# STM32F0x2 register map
File version: 1.3
CPU: CM0 r0p0, little endian, no MPU, no FPU, 2 interrupt priority bits
Registers are 32-bit, read-write, reset 0x0 unless marked. A register's access mark holds for its fields unless they carry their own. Offsets are from the block's base; [hi:lo] are bit positions; {n}, {i} and the like mark numbered series.

## WWDG — Window watchdog
Base 0x40002C00
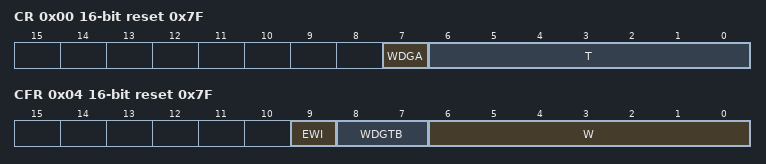
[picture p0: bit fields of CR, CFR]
0x00 CR 16-bit reset 0x7F — Control register
  [7] WDGA — Activation bit
    0=Disabled (Watchdog disabled); 1=Enabled (Watchdog enabled)
  [6:0] T — 7-bit counter
0x04 CFR 16-bit reset 0x7F — Configuration register
  [9] EWI — Early wakeup interrupt
    on write: 1=Enable (interrupt occurs whenever the counter reaches the value 0x40)
  [8:7] WDGTB — Timer base
    0=Div1 (Counter clock (PCLK1 div 4096) div 1); 1=Div2 (Counter clock (PCLK1 div 4096) div 2); 2=Div4 (Counter clock (PCLK1 div 4096) div 4); 3=Div8 (Counter clock (PCLK1 div 4096) div 8)
  [6:0] W — 7-bit window value
0x08 SR 16-bit — Status register
  [0] EWIF write-0-clears — Early wakeup interrupt flag
    on read: 0=Finished (The EWI Interrupt Service Routine has been serviced); 1=Pending (The EWI Interrupt Service Routine has been triggered) | on write: 0=Finished (The EWI Interrupt Service Routine has been serviced)

## TIM6 — Basic-timers
Base 0x40001000
Same registers: TIM7 0x40001400
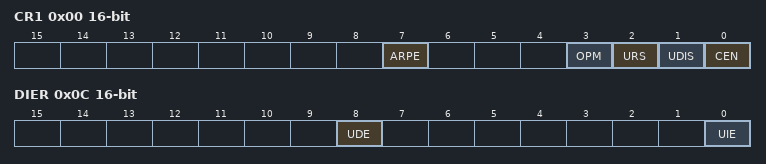
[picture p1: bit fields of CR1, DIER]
0x00 CR1 16-bit — control register 1
  [7] ARPE — Auto-reload preload enable
    0=Disabled (TIMx_APRR register is not buffered); 1=Enabled (TIMx_APRR register is buffered)
  [3] OPM — One-pulse mode
    0=Disabled (Counter is not stopped at update event); 1=Enabled (Counter stops counting at the next update event (clearing the CEN bit))
  [2] URS — Update request source
    0=AnyEvent (Any of counter overflow/underflow, setting UG, or update through slave mode, generates an update interrupt or DMA request); 1=CounterOnly (Only counter overflow/underflow generates an update interrupt or DMA request)
  [1] UDIS — Update disable
    0=Enabled (Update event enabled); 1=Disabled (Update event disabled)
  [0] CEN — Counter enable
    0=Disabled (Counter disabled); 1=Enabled (Counter enabled)
0x04 CR2 16-bit — control register 2
  [6:4] MMS — Master mode selection
    0=Reset (Use UG bit from TIMx_EGR register); 1=Enable (Use CNT bit from TIMx_CEN register); 2=Update (Use the update event)
0x0C DIER 16-bit — DMA/Interrupt enable register
  [8] UDE — Update DMA request enable
    0=Disabled (Update DMA request disabled); 1=Enabled (Update DMA request enabled)
  [0] UIE — Update interrupt enable
    0=Disabled (Update interrupt disabled); 1=Enabled (Update interrupt enabled)
0x10 SR 16-bit — status register
  [0] UIF write-0-clears — Update interrupt flag
    on read: 0=NoUpdateOccurred; 1=UpdatePending (Update interrupt pending) | on write: 0=Clear flag
0x14 EGR 16-bit wo — event generation register
  [0] UG — Update generation
    1=Update (Re-initializes the timer counter and generates an update of the registers.)
0x24 CNT 16-bit — counter
  [15:0] CNT — Low counter value
0x28 PSC 16-bit — prescaler
  [15:0] PSC — Prescaler value
0x2C ARR 16-bit reset 0xFFFF — auto-reload register
  [15:0] ARR — Low Auto-reload value

## EXTI — External interrupt/event controller
Base 0x40010400
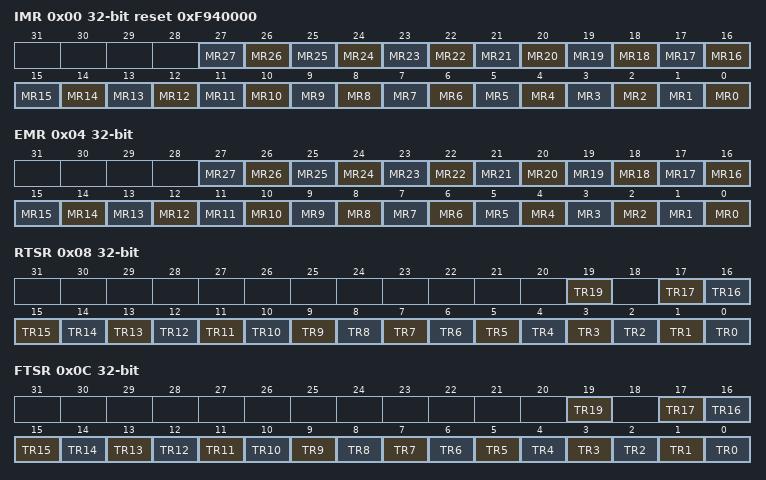
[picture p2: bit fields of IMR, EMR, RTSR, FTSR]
0x00 IMR reset 0xF940000 — Interrupt mask register (EXTI_IMR)
  [all] fields
    0=Masked (Interrupt request line is masked); 1=Unmasked (Interrupt request line is unmasked)
  [n] MR{n} (n=0..27) — Interrupt Mask on line {n}
0x04 EMR — Event mask register (EXTI_EMR)
  [all] fields
    0=Masked (Event request line is masked); 1=Unmasked (Event request line is unmasked)
  [n] MR{n} (n=0..27) — Event Mask on line {n}
0x08 RTSR — Rising Trigger selection register (EXTI_RTSR)
  [all] fields
    0=Disabled (Rising edge trigger is disabled); 1=Enabled (Rising edge trigger is enabled)
  [19] TR19 — Rising trigger event configuration of line 19
  [n] TR{n} (n=0..17) — Rising trigger event configuration of line {n}
0x0C FTSR — Falling Trigger selection register (EXTI_FTSR)
  [all] fields
    0=Disabled (Falling edge trigger is disabled); 1=Enabled (Falling edge trigger is enabled)
  [19] TR19 — Falling trigger event configuration of line 19
  [n] TR{n} (n=0..17) — Falling trigger event configuration of line {n}
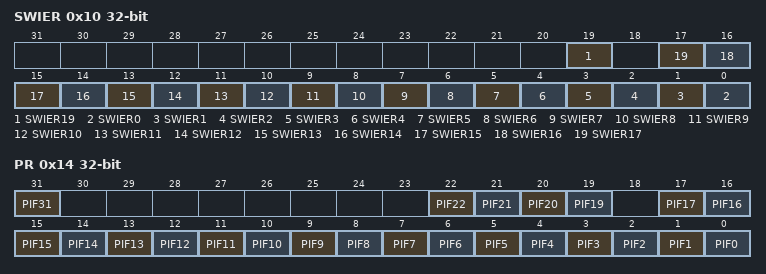
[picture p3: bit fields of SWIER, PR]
0x10 SWIER — Software interrupt event register (EXTI_SWIER)
  [all] fields
    on write: 1=Pend (Generates an interrupt request)
  [19] SWIER19 — Software Interrupt on line 19
  [n] SWIER{n} (n=0..17) — Software Interrupt on line {n}
0x14 PR — Pending register (EXTI_PR)
  [all] fields
    on read: 0=NotPending (No trigger request occurred); 1=Pending (Selected trigger request occurred) | on write: 1=Clears pending bit
  [31] PIF31 write-1-clears — Pending interrupt flag on line 31
  [n] PIF{n} write-1-clears (n=19..22) — Pending interrupt flag on line {n}
  [n] PIF{n} write-1-clears (n=0..17) — Pending interrupt flag on line {n}
